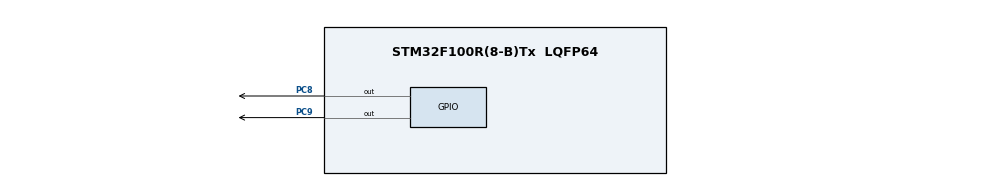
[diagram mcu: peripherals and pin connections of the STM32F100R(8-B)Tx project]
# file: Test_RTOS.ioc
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FREERTOS.Tasks01=defaultTask,24,128,StartDefaultTask,Default,NULL
Mcu.Family=STM32F1
Mcu.Name=STM32F100R(8-B)Tx
Mcu.Package=LQFP64
NVIC.PriorityGroup=NVIC_PRIORITYGROUP_4
PC8.Signal=GPIO_Output
PC9.Signal=GPIO_Output
ProjectManager.HeapSize=0x200
ProjectManager.StackSize=0x400
ProjectManager.TargetToolchain=STM32CubeIDE
RCC.APB1Freq_Value=8000000
RCC.APB2Freq_Value=8000000
VP_FREERTOS_VS_CMSIS_V2.Mode=CMSIS_V2
VP_SYS_VS_ND.Mode=No_Debug
board=custom

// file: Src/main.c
/* USER CODE BEGIN Header */
/**
  ******************************************************************************
  * @file           : main.c
  * @brief          : Main program body
  ******************************************************************************
  * @attention
  *
  * <h2><center>&copy; Copyright (c) 2019 STMicroelectronics.
  * All rights reserved.</center></h2>
  *
  * This software component is licensed by ST under Ultimate Liberty license
  * SLA0044, the "License"; You may not use this file except in compliance with
  * the License. You may obtain a copy of the License at:
  *                             www.st.com/SLA0044
  *
  ******************************************************************************
  */
/* USER CODE END Header */

#include "main.h"
#include "cmsis_os.h"

osThreadId_t defaultTaskHandle;

void SystemClock_Config(void);
static void MX_GPIO_Init(void);
void StartDefaultTask(void *argument);

int main(void)
{

  /* MCU Configuration--------------------------------------------------------*/

  /* Reset of all peripherals, Initializes the Flash interface and the Systick. */
  HAL_Init();

  /* Configure the system clock */
  SystemClock_Config();

  /* Initialize all configured peripherals */
  MX_GPIO_Init();

  osKernelInitialize();

  /* Create the thread(s) */
  /* definition and creation of defaultTask */
  const osThreadAttr_t defaultTask_attributes = {
    .name = "defaultTask",
    .priority = (osPriority_t) osPriorityNormal,
    .stack_size = 128
  };
  defaultTaskHandle = osThreadNew(StartDefaultTask, NULL, &defaultTask_attributes);

  /* Start scheduler */
  osKernelStart();

  /* We should never get here as control is now taken by the scheduler */

  /* Infinite loop */
  while (1)
  {

  }
}

void SystemClock_Config(void)
{
  RCC_OscInitTypeDef RCC_OscInitStruct = {0};
  RCC_ClkInitTypeDef RCC_ClkInitStruct = {0};

  /** Initializes the CPU, AHB and APB busses clocks
  */
  RCC_OscInitStruct.OscillatorType = RCC_OSCILLATORTYPE_HSI;
  RCC_OscInitStruct.HSIState = RCC_HSI_ON;
  RCC_OscInitStruct.HSICalibrationValue = RCC_HSICALIBRATION_DEFAULT;
  RCC_OscInitStruct.PLL.PLLState = RCC_PLL_NONE;
  if (HAL_RCC_OscConfig(&RCC_OscInitStruct) != HAL_OK)
  {
    Error_Handler();
  }
  /** Initializes the CPU, AHB and APB busses clocks
  */
  RCC_ClkInitStruct.ClockType = RCC_CLOCKTYPE_HCLK|RCC_CLOCKTYPE_SYSCLK
                              |RCC_CLOCKTYPE_PCLK1|RCC_CLOCKTYPE_PCLK2;
  RCC_ClkInitStruct.SYSCLKSource = RCC_SYSCLKSOURCE_HSI;
  RCC_ClkInitStruct.AHBCLKDivider = RCC_SYSCLK_DIV1;
  RCC_ClkInitStruct.APB1CLKDivider = RCC_HCLK_DIV1;
  RCC_ClkInitStruct.APB2CLKDivider = RCC_HCLK_DIV1;

  if (HAL_RCC_ClockConfig(&RCC_ClkInitStruct, FLASH_LATENCY_0) != HAL_OK)
  {
    Error_Handler();
  }
}

static void MX_GPIO_Init(void)
{
  GPIO_InitTypeDef GPIO_InitStruct = {0};

  /* GPIO Ports Clock Enable */
  __HAL_RCC_GPIOC_CLK_ENABLE();

  /*Configure GPIO pin Output Level */
  HAL_GPIO_WritePin(GPIOC, GPIO_PIN_8|GPIO_PIN_9, GPIO_PIN_RESET);

  /*Configure GPIO pins : PC8 PC9 */
  GPIO_InitStruct.Pin = GPIO_PIN_8|GPIO_PIN_9;
  GPIO_InitStruct.Mode = GPIO_MODE_OUTPUT_PP;
  GPIO_InitStruct.Pull = GPIO_NOPULL;
  GPIO_InitStruct.Speed = GPIO_SPEED_FREQ_LOW;
  HAL_GPIO_Init(GPIOC, &GPIO_InitStruct);

}

void StartDefaultTask(void *argument)
{
  /* USER CODE BEGIN 5 */
  /* Infinite loop */
  for(;;)
  {
    HAL_GPIO_TogglePin(GPIOC, GPIO_PIN_8); //Toggle the state of pin
    HAL_GPIO_TogglePin(GPIOC, GPIO_PIN_9); //Toggle the state of pin
    osDelay(1000); //задержка в мс
  }
  /* USER CODE END 5 */
}

void Error_Handler(void)
{
}

/************************ (C) COPYRIGHT STMicroelectronics *****END OF FILE****/
